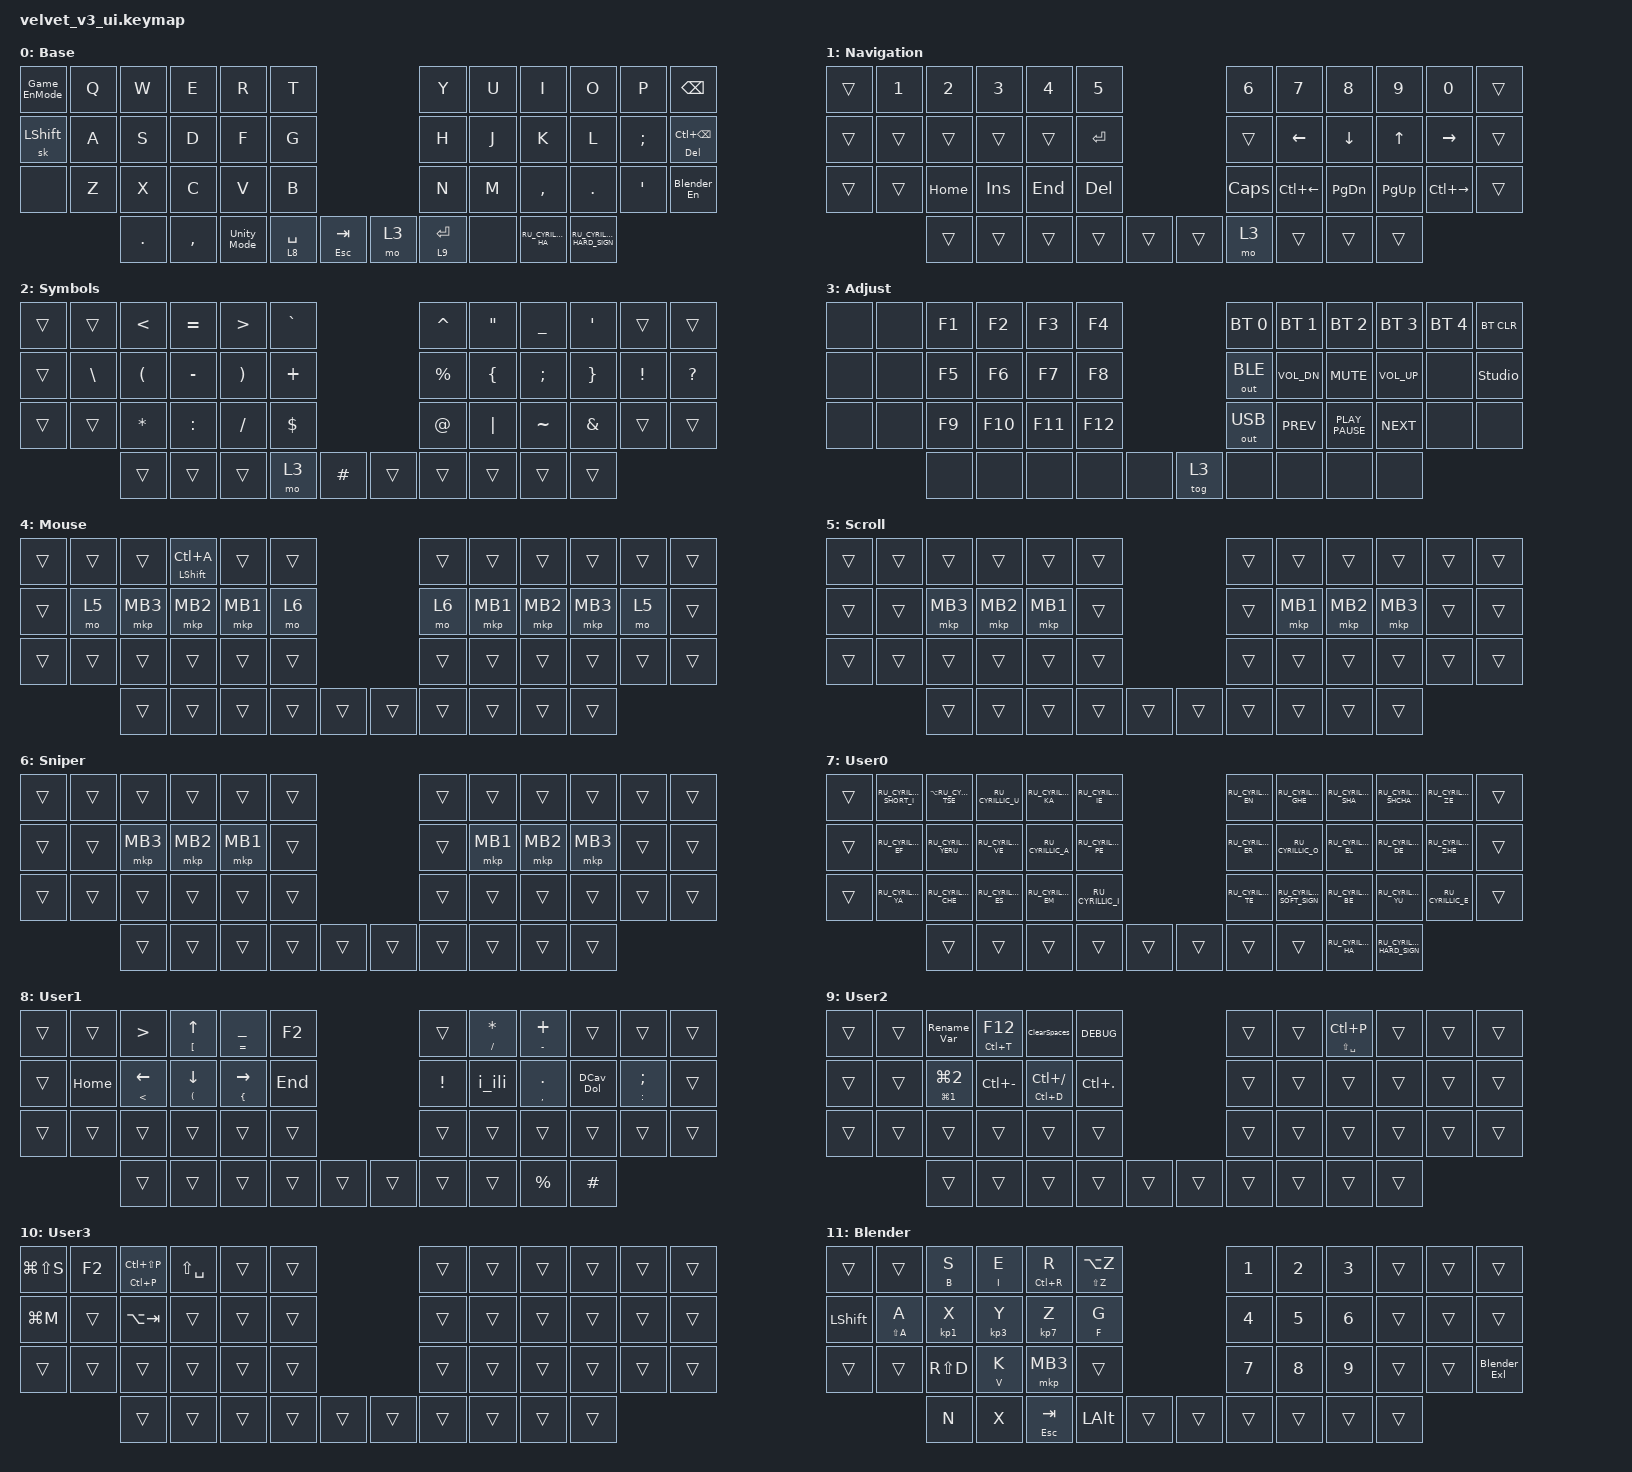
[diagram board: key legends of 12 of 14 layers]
#include "keys_ru.h"
#include <dt-bindings/zmk/input_transform.h>
#include <input/processors.dtsi>
#include <zephyr/dt-bindings/input/input-event-codes.h>
#include <behaviors.dtsi>
#include <dt-bindings/zmk/bt.h>
#include <dt-bindings/zmk/keys.h>
#include <dt-bindings/zmk/outputs.h>
#include <dt-bindings/zmk/pointing.h>

/ {
    behaviors {
        cap_sen: cap_sen {
            compatible = "zmk,behavior-hold-tap";
            label = "CAP_SEN";
            bindings = <&mo>, <&mkp>;

            #binding-cells = <2>;
            tapping-term-ms = <150>;
            hold-while-undecided;
        };

        mouse_layer: mouse_layer {
            compatible = "zmk,behavior-sticky-key";
            label = "MOUSE_LAYER";
            bindings = <&mo>;
            #binding-cells = <1>;
            release-after-ms = <200>;
        };

        Kvad: Kvad {
            compatible = "zmk,behavior-tap-dance";
            label = "KVAD";
            #binding-cells = <0>;
            bindings = <&SqBrackets>;
            tapping-term-ms = <220>;
        };

        Krug_Ugl: Krug_Ugl {
            compatible = "zmk,behavior-tap-dance";
            label = "KRUG_UGL";
            #binding-cells = <0>;
            bindings = <&Krug>, <&Uglov>;

            tapping-term-ms = <220>;
        };

        Dot_zap: Dot_zap {
            compatible = "zmk,behavior-tap-dance";
            label = "DOT_ZAP";
            #binding-cells = <0>;
            bindings = <&kp DOT>, <&kp COMMA>;

            tapping-term-ms = <220>;
        };

        ToZap_Dvoet: ToZap_Dvoet {
            compatible = "zmk,behavior-tap-dance";
            label = "TOZAP_DVOET";
            #binding-cells = <0>;
            bindings = <&kp SEMI>, <&kp COLON>;

            tapping-term-ms = <220>;
        };

        Npod_Rav: Npod_Rav {
            compatible = "zmk,behavior-tap-dance";
            label = "NPOD_RAV";
            #binding-cells = <0>;
            bindings = <&kp UNDER>, <&kp EQUAL>;

            tapping-term-ms = <220>;
        };

        Ren_Dublicate: Ren_Dublicate {
            compatible = "zmk,behavior-tap-dance";
            label = "REN_DUBLICATE";
            #binding-cells = <0>;
            tapping-term-ms = <220>;
            bindings = <&kp LC(D)>, <&Rename_Var>;
        };

        i_ili: i_ili {
            compatible = "zmk,behavior-tap-dance";
            label = "I_ILI";
            #binding-cells = <0>;
            tapping-term-ms = <220>;
            bindings = <&kp AMPERSAND>, <&double_ili>;
        };

        DCav_Dol: DCav_Dol {
            compatible = "zmk,behavior-tap-dance";
            label = "DCAV_DOL";
            #binding-cells = <0>;
            tapping-term-ms = <220>;
            bindings = <&double_Kav>, <&kp DOLLAR>;
        };

        Komit_UnCom: Komit_UnCom {
            compatible = "zmk,behavior-tap-dance";
            label = "KOMIT_UNCOM";
            #binding-cells = <0>;
            tapping-term-ms = <220>;
            bindings = <&Commit>, <&UnCom>;
        };

        ClearSpace_Save: ClearSpace_Save {
            compatible = "zmk,behavior-tap-dance";
            label = "CLEARSPACE_SAVE";
            #binding-cells = <0>;
            tapping-term-ms = <220>;
            bindings = <&kp LC(S)>, <&ClearSpaces>;
        };

        MidleB: MidleB {
            compatible = "zmk,behavior-hold-tap";
            label = "MIDLEB";
            bindings = <&MidleMouse>, <&trans>;

            #binding-cells = <2>;
            tapping-term-ms = <200>;
            hold-trigger-key-positions = <28>;
        };

        zip_auto_mouse: zip_auto_mouse {
            compatible = "zmk,input-processor-temp-layer";
            #input-processor-cells = <2>;
            require-prior-idle-ms = <800>;
            excluded-positions = <>;
        };
    };

    combos {
        compatible = "zmk,combos";

        Save {
            bindings = <&kp LC(S)>;
            key-positions = <15 16>;
            layers = <0 2 4 5 6 11 13>;
        };

        backZ {
            bindings = <&kp LC(Z)>;
            key-positions = <3 4>;
            layers = <0 2 4 5 6 11 13>;
        };

        language {
            bindings = <&kp LG(SPACE)>;
            key-positions = <14 15>;
            layers = <11 6 13 0 4 5>;
        };
    };

    macros {
        SqBrackets: SqBrackets {
            compatible = "zmk,behavior-macro";
            #binding-cells = <0>;
            bindings = <&kp LEFT_BRACKET &kp RIGHT_BRACKET &kp LEFT_ARROW>;
            label = "SQBRACKETS";
        };

        FigBrackets: FigBrackets {
            compatible = "zmk,behavior-macro";
            #binding-cells = <0>;
            bindings = <&kp LEFT_BRACE &kp RIGHT_BRACE &kp LEFT>;
            label = "FIGBRACKETS";
        };

        Krug: Krug {
            compatible = "zmk,behavior-macro";
            #binding-cells = <0>;
            bindings = <&kp LEFT_PARENTHESIS &kp RIGHT_PARENTHESIS &kp LEFT>;
            label = "KRUG";
        };

        Uglov: Uglov {
            compatible = "zmk,behavior-macro";
            #binding-cells = <0>;
            bindings = <&kp LT &kp GT &kp LEFT>;
            label = "UGLOV";
        };

        D_Tab: D_Tab {
            compatible = "zmk,behavior-macro";
            #binding-cells = <0>;
            bindings = <&kp TAB &kp TAB>;
            label = "D_TAB";
        };

        Rename_Var: Rename_Var {
            compatible = "zmk,behavior-macro";
            #binding-cells = <0>;
            bindings = <&kp LC(R) &kp LC(R)>;
            label = "RENAME_VAR";
        };

        double_Kav: double_Kav {
            compatible = "zmk,behavior-macro";
            #binding-cells = <0>;
            bindings = <&kp DQT &kp DQT>;
            label = "DOUBLE_KAV";
        };

        double_ili: double_ili {
            compatible = "zmk,behavior-macro";
            #binding-cells = <0>;
            bindings = <&kp PIPE &kp PIPE>;
            label = "DOUBLE_ILI";
        };

        Commit: Commit {
            compatible = "zmk,behavior-macro";
            #binding-cells = <0>;
            bindings = <&kp LC(K) &kp LC(C)>;
            label = "COMMIT";
        };

        UnCom: UnCom {
            compatible = "zmk,behavior-macro";
            #binding-cells = <0>;
            bindings = <&kp LC(K) &kp LC(U)>;
            label = "UNCOM";
        };

        ClearSpaces: ClearSpaces {
            compatible = "zmk,behavior-macro";
            #binding-cells = <0>;
            bindings = <&kp LC(K) &kp LC(D)>;
            label = "CLEARSPACES";
        };

        Obratno: Obratno {
            compatible = "zmk,behavior-macro";
            #binding-cells = <0>;
            bindings = <&kp LC(Z)>;
            label = "OBRATNO";
        };

        Save: Save {
            compatible = "zmk,behavior-macro";
            #binding-cells = <0>;
            bindings = <&kp LC(S)>;
            label = "SAVE";
        };

        MidleMouse: MidleMouse {
            compatible = "zmk,behavior-macro";
            #binding-cells = <0>;
            bindings = <&mkp MB3 &kp LEFT_SHIFT>;
            label = "MIDLEMOUSE";
        };

        shortcut_EN: shortcut_EN {
            compatible = "zmk,behavior-macro";
            #binding-cells = <0>;
            bindings =
                <&to 10 &kp F23>,
                <&macro_pause_for_release>,
                <&kp F24 &to 0>;

            label = "SHORTCUT_EN";
        };

        Game_EnMode: SHADER_EN {
            compatible = "zmk,behavior-macro";
            #binding-cells = <0>;
            bindings = <&to 12 &kp F22>;
            label = "SHADER_EN";
        };

        Base_Layer: SHADER_ex {
            compatible = "zmk,behavior-macro";
            #binding-cells = <0>;
            bindings = <&kp LC(F24) &to 0>;
            label = "SHADER_EX";
        };

        Blender_En: Blender_En {
            compatible = "zmk,behavior-macro";
            #binding-cells = <0>;
            bindings = <&to 11 &kp LS(F23)>;
            label = "BLENDER_EN";
        };

        Blender_Exl: Blender_Exl {
            compatible = "zmk,behavior-macro";
            #binding-cells = <0>;
            bindings = <&kp LS(F24) &to 0>;
            label = "BLENDER_EXL";
        };

        DEBUG: DEBUG {
            compatible = "zmk,behavior-macro";
            #binding-cells = <0>;
            bindings = <&kp LS(D) &kp E &kp B &kp U &kp G &kp DOT &kp LS(L) &kp O &kp G &kp LPAR &kp DLLR &kp DQT &kp LBRC &kp N &kp A &kp M &kp E &kp O &kp F &kp LPAR &kp LS(A) &kp D &kp D &kp LS(I) &kp T &kp E &kp M &kp RPAR &kp RBRC &kp COLON &kp DQT &kp RPAR>;
            label = "DEBUG";
        };

        bloodThrow: bloodThrow {
            compatible = "zmk,behavior-macro";
            #binding-cells = <0>;
            bindings = <&kp LEFT_ALT>, <&macro_wait_time 200>, <&kp C>;

            label = "BLOODTHROW";
        };

        bloodCrunch: bloodCrunch {
            compatible = "zmk,behavior-macro";
            #binding-cells = <0>;
            bindings =
                <&kp LEFT_SHIFT>,
                <&macro_wait_time 100>,
                <&kp LEFT_SHIFT>,
                <&macro_wait_time 100>,
                <&kp C>;

            label = "BLOODCRUNCH";
        };

        Unity_Mode: untiyMode {
            compatible = "zmk,behavior-macro";
            #binding-cells = <0>;
            bindings =
                <&macro_press>,
                <&mo 13>,
                <&macro_tap>,
                <&kp F23>,
                <&macro_pause_for_release>,
                <&macro_release>,
                <&mo 13>,
                <&macro_tap>,
                <&kp F24>;

            label = "UNTIYMODE";
            tap-ms = <30>;
            wait-ms = <0>;
        };

        Game_ExMode: Game_ExMode {
            compatible = "zmk,behavior-macro";
            #binding-cells = <0>;
            bindings = <&to 0 &kp F21>;
            label = "GAME_EXMODE";
        };
    };

    keymap {
        compatible = "zmk,keymap";

        base {
            bindings = <
&Game_EnMode    &kp Q  &kp W    &kp E      &kp R        &kp T                              &kp Y        &kp U  &kp I               &kp O                      &kp P     &kp BSPC
&sk LEFT_SHIFT  &kp A  &kp S    &kp D      &kp F        &kp G                              &kp H        &kp J  &kp K               &kp L                      &kp SEMI  &mt DELETE LC(BACKSPACE)
&none           &kp Z  &kp X    &kp C      &kp V        &kp B                              &kp N        &kp M  &kp COMMA           &kp DOT                    &kp SQT   &Blender_En
                       &kp DOT  &kp COMMA  &Unity_Mode  &lt 8 SPACE  &mt ESC TAB    &mo 3  &lt 9 ENTER  &none  &kp RU_CYRILLIC_HA  &kp RU_CYRILLIC_HARD_SIGN
            >;

            display-name = "Base";
        };

        nav {
            bindings = <
&trans  &kp N1  &kp N2    &kp N3   &kp N4   &kp N5                     &kp N6    &kp N7        &kp N8         &kp N9       &kp N0         &trans
&trans  &trans  &trans    &trans   &trans   &kp RET                    &trans    &kp LEFT      &kp DOWN       &kp UP       &kp RIGHT      &trans
&trans  &trans  &kp HOME  &kp INS  &kp END  &kp DEL                    &kp CLCK  &kp LC(LEFT)  &kp PAGE_DOWN  &kp PAGE_UP  &kp LC(RIGHT)  &trans
                &trans    &trans   &trans   &trans   &trans    &trans  &mo 3     &trans        &trans         &trans
            >;

            display-name = "Navigation";
        };

        sym {
            bindings = <
&trans  &trans    &kp LT    &kp EQUAL  &kp GT    &kp GRAVE                      &kp CARET  &kp DQT   &kp UNDER  &kp SQT   &trans    &trans
&trans  &kp BSLH  &kp LPAR  &kp MINUS  &kp RPAR  &kp PLUS                       &kp PRCNT  &kp LBRC  &kp SEMI   &kp RBRC  &kp EXCL  &kp QUESTION
&trans  &trans    &kp STAR  &kp COLON  &kp FSLH  &kp DLLR                       &kp AT     &kp PIPE  &kp TILDE  &kp AMPS  &trans    &trans
                  &trans    &trans     &trans    &mo 3      &kp HASH    &trans  &trans     &trans    &trans     &trans
            >;

            display-name = "Symbols";
        };

        adj {
            bindings = <
&none  &none  &kp F1  &kp F2   &kp F3   &kp F4                    &bt BT_SEL 0  &bt BT_SEL 1  &bt BT_SEL 2      &bt BT_SEL 3  &bt BT_SEL 4  &bt BT_CLR
&none  &none  &kp F5  &kp F6   &kp F7   &kp F8                    &out OUT_BLE  &kp C_VOL_DN  &kp K_MUTE        &kp C_VOL_UP  &none         &studio_unlock
&none  &none  &kp F9  &kp F10  &kp F11  &kp F12                   &out OUT_USB  &kp K_PREV    &kp K_PLAY_PAUSE  &kp K_NEXT    &none         &none
              &none   &none    &none    &none    &none    &tog 3  &none         &none         &none             &none
            >;

            display-name = "Adjust";
        };

        mouse {
            bindings = <
&trans  &trans  &trans    &mt LEFT_SHIFT LC(A)  &trans    &trans                    &trans  &trans    &trans    &trans    &trans  &trans
&trans  &mo 5   &mkp MB3  &mkp MB2              &mkp MB1  &mo 6                     &mo 6   &mkp MB1  &mkp MB2  &mkp MB3  &mo 5   &trans
&trans  &trans  &trans    &trans                &trans    &trans                    &trans  &trans    &trans    &trans    &trans  &trans
                &trans    &trans                &trans    &trans  &trans    &trans  &trans  &trans    &trans    &trans
            >;

            display-name = "Mouse";
        };

        scroll {
            bindings = <
&trans  &trans  &trans    &trans    &trans    &trans                    &trans  &trans    &trans    &trans    &trans  &trans
&trans  &trans  &mkp MB3  &mkp MB2  &mkp MB1  &trans                    &trans  &mkp MB1  &mkp MB2  &mkp MB3  &trans  &trans
&trans  &trans  &trans    &trans    &trans    &trans                    &trans  &trans    &trans    &trans    &trans  &trans
                &trans    &trans    &trans    &trans  &trans    &trans  &trans  &trans    &trans    &trans
            >;

            display-name = "Scroll";
        };

        sniper {
            bindings = <
&trans  &trans  &trans    &trans    &trans    &trans                    &trans  &trans    &trans    &trans    &trans  &trans
&trans  &trans  &mkp MB3  &mkp MB2  &mkp MB1  &trans                    &trans  &mkp MB1  &mkp MB2  &mkp MB3  &trans  &trans
&trans  &trans  &trans    &trans    &trans    &trans                    &trans  &trans    &trans    &trans    &trans  &trans
                &trans    &trans    &trans    &trans  &trans    &trans  &trans  &trans    &trans    &trans
            >;

            display-name = "Sniper";
        };

        RU {
            bindings = <
&trans  &kp RU_CYRILLIC_SHORT_I  &kp LA(RU_CYRILLIC_TSE)  &kp RU_CYRILLIC_U   &kp RU_CYRILLIC_KA  &kp RU_CYRILLIC_IE                    &kp RU_CYRILLIC_EN  &kp RU_CYRILLIC_GHE        &kp RU_CYRILLIC_SHA  &kp RU_CYRILLIC_SHCHA      &kp RU_CYRILLIC_ZE   &trans
&trans  &kp RU_CYRILLIC_EF       &kp RU_CYRILLIC_YERU     &kp RU_CYRILLIC_VE  &kp RU_CYRILLIC_A   &kp RU_CYRILLIC_PE                    &kp RU_CYRILLIC_ER  &kp RU_CYRILLIC_O          &kp RU_CYRILLIC_EL   &kp RU_CYRILLIC_DE         &kp RU_CYRILLIC_ZHE  &trans
&trans  &kp RU_CYRILLIC_YA       &kp RU_CYRILLIC_CHE      &kp RU_CYRILLIC_ES  &kp RU_CYRILLIC_EM  &kp RU_CYRILLIC_I                     &kp RU_CYRILLIC_TE  &kp RU_CYRILLIC_SOFT_SIGN  &kp RU_CYRILLIC_BE   &kp RU_CYRILLIC_YU         &kp RU_CYRILLIC_E    &trans
                                 &trans                   &trans              &trans              &trans              &trans    &trans  &trans              &trans                     &kp RU_CYRILLIC_HA   &kp RU_CYRILLIC_HARD_SIGN
            >;

            display-name = "User0";
        };

        Simvols {
            bindings = <
&trans  &trans    &kp GREATER_THAN    &mt LEFT_BRACKET UP              &mt EQUAL UNDER       &kp F2                     &trans    &mt FSLH ASTRK  &mt MINUS PLUS  &trans     &trans          &trans
&trans  &kp HOME  &mt LESS_THAN LEFT  &mt LEFT_PARENTHESIS DOWN_ARROW  &mt LEFT_BRACE RIGHT  &kp END                    &kp EXCL  &i_ili          &mt COMMA DOT   &DCav_Dol  &mt COLON SEMI  &trans
&trans  &trans    &trans              &trans                           &trans                &trans                     &trans    &trans          &trans          &trans     &trans          &trans
                  &trans              &trans                           &trans                &trans   &trans    &trans  &trans    &trans          &kp PRCNT       &kp HASH
            >;

            display-name = "User1";
        };

        Vis_Stud {
            bindings = <
&trans  &trans  &Rename_Var                    &mt LC(T) F12  &ClearSpaces         &DEBUG                         &trans  &trans  &mt LS(SPACE) LC(P)  &trans  &trans  &trans
&trans  &trans  &mt LG(NUMBER_1) LG(NUMBER_2)  &kp LC(MINUS)  &mt LC(D) LC(SLASH)  &kp LC(DOT)                    &trans  &trans  &trans               &trans  &trans  &trans
&trans  &trans  &trans                         &trans         &trans               &trans                         &trans  &trans  &trans               &trans  &trans  &trans
                &trans                         &trans         &trans               &trans       &trans    &trans  &trans  &trans  &trans               &trans
            >;

            display-name = "User2";
        };

        ShortCut {
            bindings = <
&kp LG(LS(S))  &kp F2  &mt LC(P) LC(LS(P))  &kp LS(SPACE)  &trans  &trans                    &trans  &trans  &trans  &trans  &trans  &trans
&kp LG(M)      &trans  &kp LA(TAB)          &trans         &trans  &trans                    &trans  &trans  &trans  &trans  &trans  &trans
&trans         &trans  &trans               &trans         &trans  &trans                    &trans  &trans  &trans  &trans  &trans  &trans
                       &trans               &trans         &trans  &trans  &trans    &trans  &trans  &trans  &trans  &trans
            >;

            display-name = "User3";
        };

        Blender {
            bindings = <
&trans     &trans       &mt B S            &mt I E            &mt LC(R) R        &mt LS(Z) LA(Z)                    &kp N1  &kp N2  &kp N3  &trans  &trans  &trans
&kp LSHFT  &mt LS(A) A  &mt KP_NUMBER_1 X  &mt KP_NUMBER_3 Y  &mt KP_NUMBER_7 Z  &mt F G                            &kp N4  &kp N5  &kp N6  &trans  &trans  &trans
&trans     &trans       &kp RS(D)          &mt V K            &mkp MB3           &trans                             &kp N7  &kp N8  &kp N9  &trans  &trans  &Blender_Exl
                        &kp N              &kp X              &mt ESC TAB        &kp LALT         &trans    &trans  &trans  &trans  &trans  &trans
            >;
        };

        BloodStrike {
            bindings = <
&Game_ExMode  &trans          &kp Q   &kp W   &kp E         &kp R                              &trans  &trans  &trans  &trans  &trans  &trans
&trans        &trans          &kp A   &kp S   &kp D         &kp F                              &trans  &trans  &trans  &trans  &trans  &trans
&trans        &kp LEFT_SHIFT  &trans  &kp M   &kp C         &mt Y T                            &trans  &trans  &trans  &trans  &trans  &trans
                              &trans  &trans  &kp LEFT_ALT  &kp SPACE  &kp LEFT_ALT    &trans  &trans  &trans  &trans  &trans
            >;
        };

        Unity {
            bindings = <
&trans  &trans  &trans   &kp F20  &trans   &trans                    &trans  &trans  &trans  &trans  &trans  &trans
&trans  &trans  &kp F17  &kp F19  &kp F18  &trans                    &trans  &trans  &trans  &trans  &trans  &trans
&trans  &trans  &trans   &trans   &trans   &trans                    &trans  &trans  &trans  &trans  &trans  &trans
                &trans   &trans   &trans   &trans  &trans    &trans  &trans  &trans  &trans  &trans
            >;
        };
    };
};

&trackball { cpi = <1000>; };

&trackball_listener {
    input-processors = <&zip_auto_mouse 4 500>, <&zip_xy_scaler 9 20>;

    scroller {
        layers = <5>;
        input-processors =
            <&zip_xy_transform INPUT_TRANSFORM_Y_INVERT>,
            <&zip_xy_scaler 1 32>,
            <&zip_xy_to_scroll_mapper>;
    };

    sniper {
        layers = <6>;
        input-processors = <&zip_xy_scaler 1 4>;
    };
};
